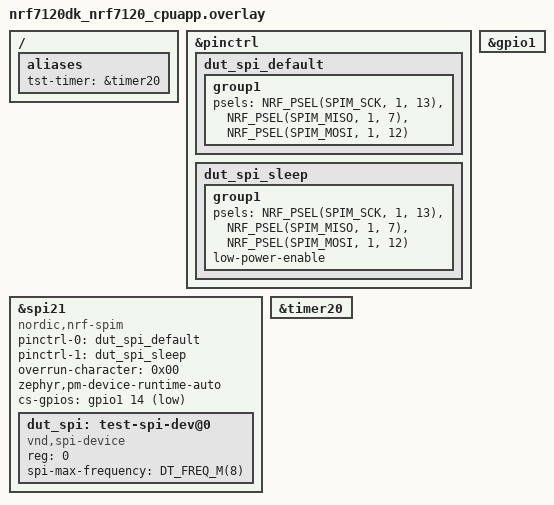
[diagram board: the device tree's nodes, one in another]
/* Required loopbacks:
 * P1.07 <-> P1.12
 */

/ {
	aliases {
		tst-timer = &timer20;
	};
};

&pinctrl {
	dut_spi_default: dut_spi_default {
		group1 {
			psels = <NRF_PSEL(SPIM_SCK, 1, 13)>,
				<NRF_PSEL(SPIM_MISO, 1, 7)>,
				<NRF_PSEL(SPIM_MOSI, 1, 12)>;
		};
	};

	dut_spi_sleep: dut_spi_sleep {
		group1 {
			psels = <NRF_PSEL(SPIM_SCK, 1, 13)>,
				<NRF_PSEL(SPIM_MISO, 1, 7)>,
				<NRF_PSEL(SPIM_MOSI, 1, 12)>;
			low-power-enable;
		};
	};
};

&spi21 {
	compatible = "nordic,nrf-spim";
	status = "okay";
	pinctrl-0 = <&dut_spi_default>;
	pinctrl-1 = <&dut_spi_sleep>;
	pinctrl-names = "default", "sleep";
	overrun-character = <0x00>;
	zephyr,pm-device-runtime-auto;
	cs-gpios = <&gpio1 14 GPIO_ACTIVE_LOW>;

	dut_spi: test-spi-dev@0 {
		compatible = "vnd,spi-device";
		reg = <0>;
		spi-max-frequency = <DT_FREQ_M(8)>;
	};
};

&gpio1 {
	status = "okay";
};

&timer20 {
	status = "okay";
};
